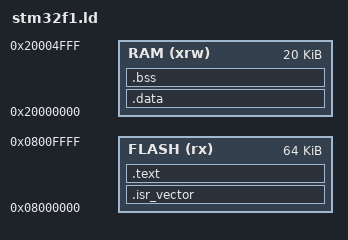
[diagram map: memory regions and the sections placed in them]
/* 链接脚本：STM32F103C8T6（64KB Flash / 20KB RAM） */
MEMORY
{
    FLASH (rx)  : ORIGIN = 0x08000000, LENGTH = 64K
    RAM   (xrw) : ORIGIN = 0x20000000, LENGTH = 20K
}

_estack = ORIGIN(RAM) + LENGTH(RAM);   /* 栈顶 = 0x20005000 */

SECTIONS
{
    .isr_vector :
    {
        . = ALIGN(4);
        KEEP(*(.isr_vector))
    } >FLASH

    .text :
    {
        . = ALIGN(4);
        *(.text*)
        *(.rodata*)
        . = ALIGN(4);
    } >FLASH

    _sidata = .;                        /* .data 的 LMA（在 Flash 中） */

    .data : AT(_sidata)
    {
        . = ALIGN(4);
        _sdata = .;
        *(.data*)
        . = ALIGN(4);
        _edata = .;
    } >RAM

    .bss :
    {
        . = ALIGN(4);
        _sbss = .;
        *(.bss*)
        *(COMMON)
        . = ALIGN(4);
        _ebss = .;
    } >RAM

    /DISCARD/ :
    {
        *(.ARM.exidx*)
        *(.ARM.attributes*)
    }
}
